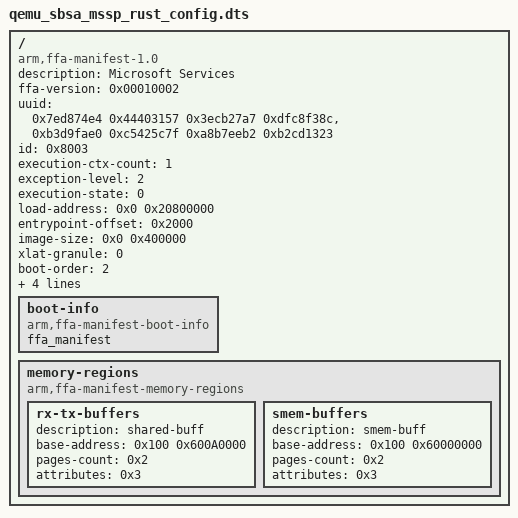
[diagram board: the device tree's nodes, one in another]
/*
 * Copyright (c) 2020-21, ARM Limited and Contributors. All rights reserved.
 * Copyright (c) Microsoft Corporation.
 *
 * SPDX-License-Identifier: BSD-3-Clause
 */

/dts-v1/;

/ {
#define MODE_SEL0	(1)
#define MODE_SEL1	(2)

#define SECURE_RO 0x1
#define SECURE_RW 0x3
#define SECURE_EXECUTE_RO 0x5
#define SECURE_EXECUTE_RW 0x7
#define NON_SECURE_RO 0x9
#define NON_SECURE_RW 0xB
#define NON_SECURE_EXECUTE_RO 0xD
#define NONSECURE_EXECUTE_RW 0xF
	/*
	 * FF-A compatible Secure Partition Manager parses the
	 * config file and fetch the following booting arguments to
	 * pass on to the Secure Partition.
	 */
	compatible = "arm,ffa-manifest-1.0";

	description = "Microsoft Services";
	ffa-version = <0x00010002>; /* 31:16 - Major, 15:0 - Minor */
	uuid = <0x7ed874e4 0x44403157 0x3ecb27a7 0xdfc8f38c>, <0xb3d9fae0 0xc5425c7f 0xa8b7eeb2 0xb2cd1323>;
	id = <0x8003>;
	execution-ctx-count = <1>;
	exception-level = <2>; /* SEL1*/
	execution-state = <0>; /* AArch64*/
	load-address = <0x0 0x20800000>;
	entrypoint-offset = <0x2000>;
	image-size = <0x0 0x400000>;
	xlat-granule = <0>; /* 4KiB */
	boot-order = <2>;
	messaging-method = <0x603>; /* Direct request/response supported. */
	ns-interrupts-action = <0>; /* Non-secure interrupt is queued */
	notification-support; /* Support receipt of notifications. */
	gp-register-num = <0>;

	boot-info {
		compatible = "arm,ffa-manifest-boot-info";
		ffa_manifest;
	};

	memory-regions {
		compatible = "arm,ffa-manifest-memory-regions";

		/*
		 * Memory shared between EL3 and S-EL0.
		 * Similar to ARM_SPM_BUF_EL0_MMAP.
		 */
		rx-tx-buffers {
			description = "shared-buff";
			base-address = <0x100 0x600A0000>;
			pages-count = <0x2>;
			attributes = <0x3>;
		};

		/*
		 * Memory shared between S-EL0 and NS-EL1.
		 * Similar to ARM_SPM_BUF_NS_MMAP.
		 */
		smem-buffers {
			description = "smem-buff";
			base-address = <0x100 0x60000000>;
			pages-count = <0x2>;
			attributes = <0x3>;
		};
	};
};
